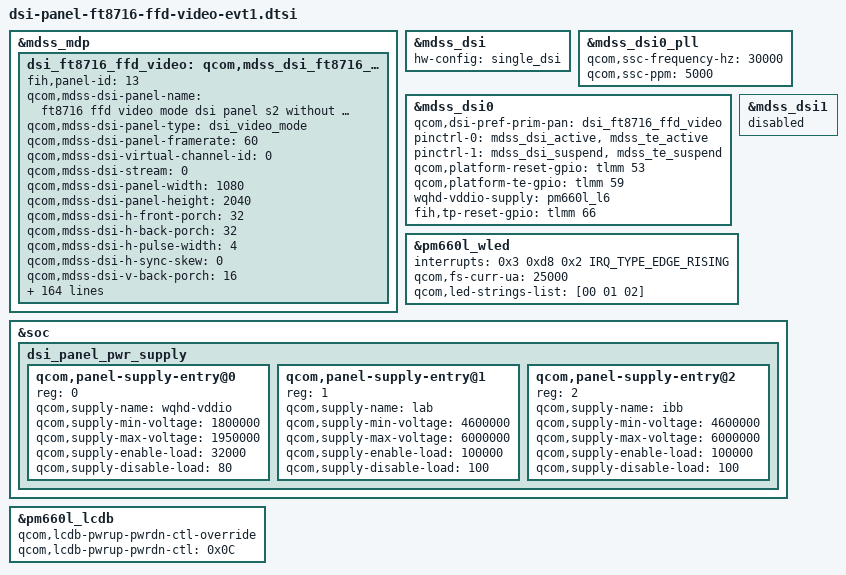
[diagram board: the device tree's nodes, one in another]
/* Copyright (c) 2015, The Linux Foundation. All rights reserved.
 *
 * This program is free software; you can redistribute it and/or modify
 * it under the terms of the GNU General Public License version 2 and
 * only version 2 as published by the Free Software Foundation.
 *
 * This program is distributed in the hope that it will be useful,
 * but WITHOUT ANY WARRANTY; without even the implied warranty of
 * MERCHANTABILITY or FITNESS FOR A PARTICULAR PURPOSE.  See the
 * GNU General Public License for more details.
 */

/*---------------------------------------------------------------------------
 * Templated from dsi-panel-r69006-1080p-video.dtsi
 *---------------------------------------------------------------------------*/
&mdss_mdp {
	dsi_ft8716_ffd_video: qcom,mdss_dsi_ft8716_ffd_video_s2 {
		fih,panel-id = <13>;
		qcom,mdss-dsi-panel-name = "ft8716 ffd video mode dsi panel s2 without DSC";
		qcom,mdss-dsi-panel-type = "dsi_video_mode";
		qcom,mdss-dsi-panel-framerate = <60>;
		qcom,mdss-dsi-virtual-channel-id = <0>;
		qcom,mdss-dsi-stream = <0>;
		qcom,mdss-dsi-panel-width = <1080>;
		qcom,mdss-dsi-panel-height = <2040>;
		qcom,mdss-dsi-h-front-porch = <32>;
		qcom,mdss-dsi-h-back-porch = <32>;
		qcom,mdss-dsi-h-pulse-width = <4>;
		qcom,mdss-dsi-h-sync-skew = <0>;
		qcom,mdss-dsi-v-back-porch = <16>;
		qcom,mdss-dsi-v-front-porch = <16>;
		qcom,mdss-dsi-v-pulse-width = <2>;
		qcom,mdss-dsi-h-left-border = <0>;
		qcom,mdss-dsi-h-right-border = <0>;
		qcom,mdss-dsi-v-top-border = <0>;
		qcom,mdss-dsi-v-bottom-border = <0>;
		qcom,mdss-dsi-bpp = <24>;
		qcom,mdss-dsi-underflow-color = <0xff>;
		qcom,mdss-dsi-border-color = <0>;
		qcom,mdss-dsi-on-command = [
			// ENABLE CMD2
			29 00 00 00 00 00 02 00 80
			29 00 00 00 00 00 03 FF 00 00
			29 00 00 00 00 00 04 FF 87 16 01
			29 00 00 00 00 00 02 00 80
			29 01 00 00 00 00 03 FF 87 16
			// Config WA
			29 01 00 00 00 00 02 00 80
			29 01 00 00 00 00 0D D8 00 00 00 00 00 00 00 00 02 04 04 06
			29 01 00 00 00 00 02 00 90
			29 01 00 00 00 00 0D D8 01 02 02 04 06 08 0a 0a 0b 0a 0b 0a
			29 01 00 00 00 00 02 00 A0
			29 01 00 00 00 00 0D D8 00 02 02 03 04 06 08 0a 0d 0f 10 13
			29 01 00 00 00 00 02 00 B0
			29 01 00 00 00 00 0D D8 00 00 00 00 01 01 00 00 81 82 82 83
			29 01 00 00 00 00 02 00 C0
			29 01 00 00 00 00 0D D8 84 8a 8d 93 9c a6 af b8 c1 c5 c5 c7
			29 01 00 00 00 00 02 00 D0
			29 01 00 00 00 00 0D D8 02 06 08 0a 10 15 1a 1e 21 22 23 24
			29 01 00 00 00 00 02 00 E0
			29 01 00 00 00 00 04 D8 f7 ee e6
			29 01 00 00 00 00 02 00 C0
			29 01 00 00 00 00 02 D7 41
			// DGAMMA OFF
			29 01 00 00 00 00 02 00 A0
			29 01 00 00 00 00 02 D7 05
			// CE
			29 00 00 00 00 00 02 00 A0
			29 01 00 00 00 00 0D D6 10 09 04 00 00 00 0C 19 13 16 17 16
			29 00 00 00 00 00 02 00 B0
			29 01 00 00 00 00 0D D6 8D 88 87 78 5E 3C 33 33 56 6D 79 84
			29 00 00 00 00 00 02 00 C0
			29 01 00 00 00 00 0D D6 80 80 72 65 55 48 44 55 6B 6F 76 7F
			29 00 00 00 00 00 02 00 D0
			29 01 00 00 00 00 0D D6 67 6A 4F 47 3A 39 36 53 57 5D 5A 58
			// AIE V3
			29 01 00 00 00 00 02 00 01
			29 01 00 00 00 00 02 C6 10
			29 01 00 00 00 00 02 00 00
			29 01 00 00 00 00 13 C8 90 78 56 34 33 33 33 33 33 33 43 44 43 44 44 44 44 54
			29 01 00 00 00 00 02 00 01
			29 01 00 00 00 00 02 C6 11
			29 01 00 00 00 00 02 00 00
			29 01 00 00 00 00 13 C8 90 78 56 34 33 33 22 33 33 43 44 44 43 44 44 44 44 54
			29 01 00 00 00 00 02 00 01
			29 01 00 00 00 00 02 C6 12
			29 01 00 00 00 00 02 00 00
			29 01 00 00 00 00 13 C8 E0 8C 56 33 33 33 33 33 33 33 23 22 33 43 44 44 44 44
			29 01 00 00 00 00 02 00 01
			29 01 00 00 00 00 02 C6 00
			// DISABLE CMD2
			29 00 00 00 00 00 02 00 00
			29 01 00 00 00 00 04 FF 00 00 00
			// ??
			29 00 00 00 00 00 02 00 80
			29 00 00 00 00 00 03 FF 00 00
			// DSI ON
			05 01 00 00 78 00 02 11 00
			05 01 00 00 0a 00 02 35 00
			05 01 00 00 00 00 02 29 00
		];
		qcom,mdss-dsi-off-command = [05 01 00 00 14 00 02 28 00
				 05 01 00 00 78 00 02 10 00];
		qcom,mdss-dsi-on-command-state = "dsi_lp_mode";
		qcom,mdss-dsi-off-command-state = "dsi_hs_mode";
		qcom,mdss-dsi-h-sync-pulse = <0>;
		qcom,mdss-dsi-traffic-mode = "non_burst_sync_event";
		qcom,mdss-dsi-bllp-eof-power-mode;
		qcom,mdss-dsi-bllp-power-mode;
		qcom,mdss-dsi-lane-0-state;
		qcom,mdss-dsi-lane-1-state;
		qcom,mdss-dsi-lane-2-state;
		qcom,mdss-dsi-lane-3-state;
		qcom,mdss-dsi-t-clk-post = <0x0d>;
		qcom,mdss-dsi-t-clk-pre = <0x2d>;
		qcom,esd-check-enabled;
		qcom,mdss-dsi-panel-status-check-mode = "reg_read";
		qcom,mdss-dsi-panel-status-command = [06 01 00 01 00 00 01 0a
		06 01 00 01 00 00 01 0b
		06 01 00 01 00 00 01 0c
		06 01 00 01 00 00 01 0d
		06 01 00 01 00 00 01 0e];
		qcom,mdss-dsi-panel-status-command-state = "dsi_hs_mode";
		qcom,mdss-dsi-panel-status-value = <0x9c>,<0x00>,<0x07>,<0x00>,<0x80>;
		qcom,mdss-dsi-panel-on-check-value = <0x9c>,<0x00>,<0x07>,<0x00>,<0x80>;
		qcom,mdss-dsi-panel-status-read-length = <1>,<1>,<1>,<1>,<1>;
		qcom,mdss-dsi-panel-max-error-count = <3>;
		qcom,mdss-dsi-dma-trigger = "trigger_sw";
		qcom,mdss-dsi-mdp-trigger = "none";
		qcom,mdss-dsi-reset-sequence = <1 1>, <0 1>, <1 15>;

		// dynamic : value 1
		qcom,mdss-dsi-ce-on-command = [
			29 01 00 00 00 00 03 91 00 00
		];

		qcom,mdss-dsi-ce-on-command-test1 = [
			29 01 00 00 00 00 03 91 C0 00
		];

		qcom,mdss-dsi-ce-on-command-test2 = [
			29 01 00 00 00 00 03 91 FF 00
		];

		// standard : value 0
		qcom,mdss-dsi-ce-off-command = [
			29 01 00 00 00 00 03 91 80 00
		];

		qcom,mdss-dsi-ct-normal-command = [
			// Enable CMD2
			29 00 00 00 00 00 04 FF 87 16 01
			29 00 00 00 00 00 02 00 80
			29 01 00 00 00 00 03 FF 87 16
			// Gamma Channel
			29 00 00 00 00 00 02 00 A0
			29 01 00 00 00 00 02 D7 05
			// Select White Point
			29 00 00 00 00 00 02 00 00
			29 01 00 00 00 00 02 94 CA
			// Disable CMD2
			29 00 00 00 00 00 02 00 00
			29 00 00 00 00 00 04 FF 00 00 00
			29 00 00 00 00 00 02 00 80
			29 01 00 00 00 00 03 FF 00 00
		];

		qcom,mdss-dsi-ct-warm-command = [
			// Enable CMD2
			29 00 00 00 00 00 04 FF 87 16 01
			29 00 00 00 00 00 02 00 80
			29 01 00 00 00 00 03 FF 87 16
			// Gamma Channel
			29 00 00 00 00 00 02 00 A0
			29 01 00 00 00 00 02 D7 05
			// Select White Point
			29 00 00 00 00 00 02 00 00
			29 01 00 00 00 00 02 94 D2
			// Disable CMD2
			29 00 00 00 00 00 02 00 00
			29 00 00 00 00 00 04 FF 00 00 00
			29 00 00 00 00 00 02 00 80
			29 01 00 00 00 00 03 FF 00 00
		];

		qcom,mdss-dsi-ct-cold-command = [
			// Enable CMD2
			29 00 00 00 00 00 04 FF 87 16 01
			29 00 00 00 00 00 02 00 80
			29 01 00 00 00 00 03 FF 87 16
			// Gamma Channel
			29 00 00 00 00 00 02 00 A0
			29 01 00 00 00 00 02 D7 05
			// Select White Point
			29 00 00 00 00 00 02 00 00
			29 01 00 00 00 00 02 94 A0
			// Disable CMD2
			29 00 00 00 00 00 02 00 00
			29 00 00 00 00 00 04 FF 00 00 00
			29 00 00 00 00 00 02 00 80
			29 01 00 00 00 00 03 FF 00 00
		];

		// Long packet
		qcom,mdss-dsi-ct-warm-command-backup-1= [
			// ENABLE CMD2
			29 00 00 00 00 00 04 FF 87 16 01
			29 00 00 00 00 00 02 00 80
			29 00 00 00 00 00 03 FF 87 16
			// 0xD7A0 = 0x05
			29 00 00 00 00 00 02 00 A0
			29 01 00 00 00 00 02 D7 05
			// WARM
			29 00 00 00 00 00 02 00 00
			29 01 00 00 00 00 10 EC 00 04 08 0C 00 10 14 18 1C 00 20 28 30 38 F0
			29 00 00 00 00 00 02 00 10
			29 01 00 00 00 00 10 EC 40 49 51 59 6E 61 69 71 79 54 81 89 91 99 55
			29 00 00 00 00 00 02 00 20
			29 01 00 00 00 00 10 EC A1 A9 B0 B9 21 C0 C8 D0 D8 03 E0 E8 F0 F8 00
			29 00 00 00 00 00 02 00 30
			29 01 00 00 00 00 05 EC FC FE FF 00
			29 00 00 00 00 00 02 00 00
			29 01 00 00 00 00 10 ED 00 03 07 0B 18 0E 12 16 19 C6 1D 24 2C 33 8D
			29 00 00 00 00 00 02 00 10
			29 01 00 00 00 00 10 ED 3A 42 49 51 37 58 5F 67 6F 2D 76 7D 85 8C 8D
			29 00 00 00 00 00 02 00 20
			29 01 00 00 00 00 10 ED 93 9A A2 A9 8F B1 B8 BF C7 28 CE D5 DD E5 0D
			29 00 00 00 00 00 02 00 30
			29 01 00 00 00 00 05 ED E8 EA EB 0F
			29 00 00 00 00 00 02 00 00
			29 01 00 00 00 00 10 EE 00 03 07 0A 88 0E 11 15 18 08 1A 22 2A 31 5F
			29 00 00 00 00 00 02 00 10
			29 01 00 00 00 00 10 EE 38 3F 46 4D 55 54 5B 62 69 E9 70 78 7F 86 03
			29 00 00 00 00 00 02 00 20
			29 01 00 00 00 00 10 EE 8D 93 9B A2 58 A9 B0 B7 BE A5 C5 CC D3 DA F2
			29 00 00 00 00 00 02 00 30
			29 01 00 00 00 00 05 EE DE E0 E1 01
			// 0xD7A0 = 0x00
			29 00 00 00 00 00 02 00 A0
			29 00 00 00 00 00 02 D7 00
			// DISABLE CMD2
			29 00 00 00 00 00 02 00 00
			29 01 00 00 00 00 04 FF 00 00 00
		];

		// Long packet with 3 parameters
		qcom,mdss-dsi-ct-warm-command-backup-2 = [
			29 00 00 00 00 00 02 00 00
			29 00 00 00 00 00 04 FF 87 16 01
			29 00 00 00 00 00 02 00 80
			29 01 00 00 00 00 03 FF 87 16
			15 00 00 00 00 00 02 00 A0
			15 01 00 00 00 00 02 D7 00
			// GAMMA
			29 00 00 00 00 00 02 00 00
			29 01 00 00 00 00 04 EC 00 03 07
			29 00 00 00 00 00 02 00 03
			29 01 00 00 00 00 04 EC 0B 18 0E
			29 00 00 00 00 00 02 00 06
			29 01 00 00 00 00 04 EC 12 16 1A
			29 00 00 00 00 00 02 00 09
			29 01 00 00 00 00 04 EC 9B 1E 26
			29 00 00 00 00 00 02 00 0C
			29 01 00 00 00 00 04 EC 2D 34 D1
			29 00 00 00 00 00 02 00 10
			29 01 00 00 00 00 04 EC 3C 44 4C
			29 00 00 00 00 00 02 00 13
			29 01 00 00 00 00 04 EC 54 1E 5B
			29 00 00 00 00 00 02 00 16
			29 01 00 00 00 00 04 EC 63 6A 71
			29 00 00 00 00 00 02 00 19
			29 01 00 00 00 00 04 EC 96 79 80
			29 00 00 00 00 00 02 00 1C
			29 01 00 00 00 00 04 EC 87 8F F4
			29 00 00 00 00 00 02 00 20
			29 01 00 00 00 00 04 EC 95 9D A5
			29 00 00 00 00 00 02 00 23
			29 01 00 00 00 00 04 EC AC 8B B4
			29 00 00 00 00 00 02 00 26
			29 01 00 00 00 00 04 EC BB C3 CA
			29 00 00 00 00 00 02 00 29
			29 01 00 00 00 00 04 EC 89 D2 D9
			29 00 00 00 00 00 02 00 2C
			29 01 00 00 00 00 04 EC E1 E8 48
			29 00 00 00 00 00 02 00 30
			29 01 00 00 00 00 04 EC EC EE EF
			29 00 00 00 00 00 02 00 33
			29 01 00 00 00 00 02 EC 00
			29 00 00 00 00 00 02 00 00
			29 01 00 00 00 00 04 ED 00 03 07
			29 00 00 00 00 00 02 00 03
			29 01 00 00 00 00 04 ED 0B 6C 0F
			29 00 00 00 00 00 02 00 06
			29 01 00 00 00 00 04 ED 13 16 1A
			29 00 00 00 00 00 02 00 09
			29 01 00 00 00 00 04 ED 70 1E 25
			29 00 00 00 00 00 02 00 0C
			29 01 00 00 00 00 04 ED 2D 35 6C
			29 00 00 00 00 00 02 00 10
			29 01 00 00 00 00 04 ED 3C 44 4C
			29 00 00 00 00 00 02 00 13
			29 01 00 00 00 00 04 ED 53 CB 5B
			29 00 00 00 00 00 02 00 16
			29 01 00 00 00 00 04 ED 63 6A 72
			29 00 00 00 00 00 02 00 19
			29 01 00 00 00 00 04 ED 61 79 81
			29 00 00 00 00 00 02 00 1C
			29 01 00 00 00 00 04 ED 89 90 CB
			29 00 00 00 00 00 02 00 20
			29 01 00 00 00 00 04 ED 98 A0 A7
			29 00 00 00 00 00 02 00 23
			29 01 00 00 00 00 04 ED AF 61 B6
			29 00 00 00 00 00 02 00 26
			29 01 00 00 00 00 04 ED BE C6 CD
			29 00 00 00 00 00 02 00 29
			29 01 00 00 00 00 04 ED CB D5 DD
			29 00 00 00 00 00 02 00 2C
			29 01 00 00 00 00 04 ED E4 EC 71
			29 00 00 00 00 00 02 00 30
			29 01 00 00 00 00 04 ED F0 F2 F3
			29 00 00 00 00 00 02 00 33
			29 01 00 00 00 00 02 ED 00
			29 00 00 00 00 00 02 00 00
			29 01 00 00 00 00 04 EE 00 04 07
			29 00 00 00 00 00 02 00 03
			29 01 00 00 00 00 04 EE 0B F0 0F
			29 00 00 00 00 00 02 00 06
			29 01 00 00 00 00 04 EE 12 16 1A
			29 00 00 00 00 00 02 00 09
			29 01 00 00 00 00 04 EE BD 1E 26
			29 00 00 00 00 00 02 00 0C
			29 01 00 00 00 00 04 EE 2E 36 2A
			29 00 00 00 00 00 02 00 10
			29 01 00 00 00 00 04 EE 3D 45 4E
			29 00 00 00 00 00 02 00 13
			29 01 00 00 00 00 04 EE 55 CF 5D
			29 00 00 00 00 00 02 00 16
			29 01 00 00 00 00 04 EE 65 6C 74
			29 00 00 00 00 00 02 00 19
			29 01 00 00 00 00 04 EE 71 7B 83
			29 00 00 00 00 00 02 00 1C
			29 01 00 00 00 00 04 EE 8B 93 FE
			29 00 00 00 00 00 02 00 20
			29 01 00 00 00 00 04 EE 9B A3 AB
			29 00 00 00 00 00 02 00 23
			29 01 00 00 00 00 04 EE B3 BF BB
			29 00 00 00 00 00 02 00 26
			29 01 00 00 00 00 04 EE C3 CB D4
			29 00 00 00 00 00 02 00 29
			29 01 00 00 00 00 04 EE 7B DC E6
			29 00 00 00 00 00 02 00 2C
			29 01 00 00 00 00 04 EE EE F7 39
			29 00 00 00 00 00 02 00 30
			29 01 00 00 00 00 04 EE FB FD FF
			29 00 00 00 00 00 02 00 33
			29 01 00 00 00 00 04 EE 09
			// DISABLE CMD2
			29 00 00 00 00 00 02 00 00
			29 01 00 00 00 00 04 FF 00 00 00
		];

		// Shart packet with 1 parameter
		qcom,mdss-dsi-ct-warm-command-backup-3 = [
			29 00 00 00 00 00 02 00 00
			29 00 00 00 00 00 04 FF 87 16 01
			29 00 00 00 00 00 02 00 80
			29 01 00 00 00 00 03 FF 87 16

			15 00 00 00 00 00 02 00 A0
			15 01 00 00 00 00 02 D7 00

			//00 04 08 0C 00 10 14 18 1C 00 20 28 30 38 F0
			15 00 00 00 00 00 02 00 00
			15 00 00 00 00 00 02 EC 00
			15 00 00 00 00 00 02 00 01
			15 00 00 00 00 00 02 EC 04
			15 00 00 00 00 00 02 00 02
			15 00 00 00 00 00 02 EC 08
			15 00 00 00 00 00 02 00 03
			15 00 00 00 00 00 02 EC 0C
			15 00 00 00 00 00 02 00 04
			15 00 00 00 00 00 02 EC 00
			15 00 00 00 00 00 02 00 05
			15 00 00 00 00 00 02 EC 10
			15 00 00 00 00 00 02 00 06
			15 00 00 00 00 00 02 EC 14
			15 00 00 00 00 00 02 00 07
			15 00 00 00 00 00 02 EC 18
			15 00 00 00 00 00 02 00 08
			15 00 00 00 00 00 02 EC 1C
			15 00 00 00 00 00 02 00 09
			15 00 00 00 00 00 02 EC 00
			15 00 00 00 00 00 02 00 0A
			15 00 00 00 00 00 02 EC 20
			15 00 00 00 00 00 02 00 0B
			15 00 00 00 00 00 02 EC 28
			15 00 00 00 00 00 02 00 0C
			15 00 00 00 00 00 02 EC 30
			15 00 00 00 00 00 02 00 0D
			15 00 00 00 00 00 02 EC 38
			15 00 00 00 00 00 02 00 0E
			15 00 00 00 00 00 02 EC F0

			// 40 49 51 59 6E 61 69 71 79 54 81 89 91 99 55
			15 00 00 00 00 00 02 00 10
			15 00 00 00 00 00 02 EC 40
			15 00 00 00 00 00 02 00 11
			15 00 00 00 00 00 02 EC 49
			15 00 00 00 00 00 02 00 12
			15 00 00 00 00 00 02 EC 51
			15 00 00 00 00 00 02 00 13
			15 00 00 00 00 00 02 EC 59
			15 00 00 00 00 00 02 00 14
			15 00 00 00 00 00 02 EC 6E
			15 00 00 00 00 00 02 00 15
			15 00 00 00 00 00 02 EC 61
			15 00 00 00 00 00 02 00 16
			15 00 00 00 00 00 02 EC 69
			15 00 00 00 00 00 02 00 17
			15 00 00 00 00 00 02 EC 71
			15 00 00 00 00 00 02 00 18
			15 00 00 00 00 00 02 EC 79
			15 00 00 00 00 00 02 00 19
			15 00 00 00 00 00 02 EC 54
			15 00 00 00 00 00 02 00 1A
			15 00 00 00 00 00 02 EC 81
			15 00 00 00 00 00 02 00 1B
			15 00 00 00 00 00 02 EC 89
			15 00 00 00 00 00 02 00 1C
			15 00 00 00 00 00 02 EC 91
			15 00 00 00 00 00 02 00 1D
			15 00 00 00 00 00 02 EC 99
			15 00 00 00 00 00 02 00 1E
			15 00 00 00 00 00 02 EC 55

			// A1 A9 B0 B9 21 C0 C8 D0 D8 03 E0 E8 F0 F8 00
			15 00 00 00 00 00 02 00 20
			15 00 00 00 00 00 02 EC A1
			15 00 00 00 00 00 02 00 21
			15 00 00 00 00 00 02 EC A9
			15 00 00 00 00 00 02 00 22
			15 00 00 00 00 00 02 EC B0
			15 00 00 00 00 00 02 00 23
			15 00 00 00 00 00 02 EC B9
			15 00 00 00 00 00 02 00 24
			15 00 00 00 00 00 02 EC 21
			15 00 00 00 00 00 02 00 25
			15 00 00 00 00 00 02 EC C0
			15 00 00 00 00 00 02 00 26
			15 00 00 00 00 00 02 EC C8
			15 00 00 00 00 00 02 00 27
			15 00 00 00 00 00 02 EC D0
			15 00 00 00 00 00 02 00 28
			15 00 00 00 00 00 02 EC D8
			15 00 00 00 00 00 02 00 29
			15 00 00 00 00 00 02 EC 03
			15 00 00 00 00 00 02 00 2A
			15 00 00 00 00 00 02 EC E0
			15 00 00 00 00 00 02 00 2B
			15 00 00 00 00 00 02 EC E8
			15 00 00 00 00 00 02 00 2C
			15 00 00 00 00 00 02 EC F0
			15 00 00 00 00 00 02 00 2D
			15 00 00 00 00 00 02 EC F8
			15 00 00 00 00 00 02 00 2E
			15 00 00 00 00 00 02 EC 00

			// FC FE FF 00
			15 00 00 00 00 00 02 00 30
			15 00 00 00 00 00 02 EC FC
			15 00 00 00 00 00 02 00 31
			15 00 00 00 00 00 02 EC FE
			15 00 00 00 00 00 02 00 32
			15 00 00 00 00 00 02 EC FF
			15 00 00 00 00 00 02 00 33
			15 01 00 00 00 00 02 EC 00

			//15 00 00 00 00 00 02 00 A0
			//15 00 00 00 00 00 02 D7 00

			29 00 00 00 00 00 02 00 00
			29 01 00 00 00 00 04 FF 00 00 00
		];

		qcom,mdss-dsi-ct-cold-command-backup-1 = [
			// ENABLE CMD2
			29 00 00 00 00 00 04 FF 87 16 01
			29 00 00 00 00 00 02 00 80
			29 00 00 00 00 00 03 FF 87 16
			// 0xD7A0 = 0x05
			29 00 00 00 00 00 02 00 A0
			29 01 00 00 00 00 02 D7 05
			// COLD
			29 00 00 00 00 00 02 00 00
			29 01 00 00 00 00 10 EC 00 03 07 0B 18 0E 12 16 1A 9B 1E 26 2D 34 D1
			29 00 00 00 00 00 02 00 10
			29 01 00 00 00 00 10 EC 3C 44 4C 54 1E 5B 63 6A 71 96 79 80 87 8F F4
			29 00 00 00 00 00 02 00 20
			29 01 00 00 00 00 10 EC 95 9D A5 AC 8B B4 BB C3 CA 89 D2 D9 E1 E8 48
			29 00 00 00 00 00 02 00 30
			29 01 00 00 00 00 05 EC EC EE EF 00
			29 00 00 00 00 00 02 00 00
			29 01 00 00 00 00 10 ED 00 03 07 0B 6C 0F 13 16 1A 70 1E 25 2D 35 6C
			29 00 00 00 00 00 02 00 10
			29 01 00 00 00 00 10 ED 3C 44 4C 53 CB 5B 63 6A 72 61 79 81 89 90 CB
			29 00 00 00 00 00 02 00 20
			29 01 00 00 00 00 10 ED 98 A0 A7 AF 61 B6 BE C6 CD CB D5 DD E4 EC 71
			29 00 00 00 00 00 02 00 30
			29 01 00 00 00 00 05 ED F0 F2 F3 00
			29 00 00 00 00 00 02 00 00
			29 01 00 00 00 00 10 EE 00 04 07 0B F0 0F 12 16 1A BD 1E 26 2E 36 2A
			29 00 00 00 00 00 02 00 10
			29 01 00 00 00 00 10 EE 3D 45 4E 55 CF 5D 65 6C 74 71 7B 83 8B 93 FE
			29 00 00 00 00 00 02 00 20
			29 01 00 00 00 00 10 EE 9B A3 AB B3 BF BB C3 CB D4 7B DC E6 EE F7 39
			29 00 00 00 00 00 02 00 30
			29 01 00 00 00 00 05 EE FB FD FF 09
			// 0xD7A0 = 0x00
			29 00 00 00 00 00 02 00 A0
			29 00 00 00 00 00 02 D7 00
			// DISABLE CMD2
			29 00 00 00 00 00 02 00 00
			29 01 00 00 00 00 04 FF 00 00 00
		];

		qcom,mdss-dsi-blf-10-command = [
			// Enable CMD2
			29 00 00 00 00 00 04 FF 87 16 01
			29 00 00 00 00 00 02 00 80
			29 01 00 00 00 00 03 FF 87 16
			// Gamma Channel
			29 00 00 00 00 00 02 00 A0
			29 01 00 00 00 00 02 D7 05
			// Select White Point
			29 00 00 00 00 00 02 00 00
			29 01 00 00 00 00 02 94 CC
			// Disable CMD2
			29 00 00 00 00 00 02 00 00
			29 00 00 00 00 00 04 FF 00 00 00
			29 00 00 00 00 00 02 00 80
			29 01 00 00 00 00 03 FF 00 00
		];

		qcom,mdss-dsi-blf-30-command = [
			// Enable CMD2
			29 00 00 00 00 00 04 FF 87 16 01
			29 00 00 00 00 00 02 00 80
			29 01 00 00 00 00 03 FF 87 16
			// Gamma Channel
			29 00 00 00 00 00 02 00 A0
			29 01 00 00 00 00 02 D7 05
			// Select White Point
			29 00 00 00 00 00 02 00 00
			29 01 00 00 00 00 02 94 DC
			// Disable CMD2
			29 00 00 00 00 00 02 00 00
			29 00 00 00 00 00 04 FF 00 00 00
			29 00 00 00 00 00 02 00 80
			29 01 00 00 00 00 03 FF 00 00
		];

		qcom,mdss-dsi-blf-50-command = [
			// Enable CMD2
			29 00 00 00 00 00 04 FF 87 16 01
			29 00 00 00 00 00 02 00 80
			29 01 00 00 00 00 03 FF 87 16
			// Gamma Channel
			29 00 00 00 00 00 02 00 A0
			29 01 00 00 00 00 02 D7 05
			// Select White Point
			29 00 00 00 00 00 02 00 00
			29 01 00 00 00 00 02 94 EF
			// Disable CMD2
			29 00 00 00 00 00 02 00 00
			29 00 00 00 00 00 04 FF 00 00 00
			29 00 00 00 00 00 02 00 80
			29 01 00 00 00 00 03 FF 00 00
		];

		qcom,mdss-dsi-blf-75-command = [
			// Enable CMD2
			29 00 00 00 00 00 04 FF 87 16 01
			29 00 00 00 00 00 02 00 80
			29 01 00 00 00 00 03 FF 87 16
			// Gamma Channel
			29 00 00 00 00 00 02 00 A0
			29 01 00 00 00 00 02 D7 05
			// Select White Point
			29 00 00 00 00 00 02 00 00
			29 01 00 00 00 00 02 94 FF
			// Disable CMD2
			29 00 00 00 00 00 02 00 00
			29 00 00 00 00 00 04 FF 00 00 00
			29 00 00 00 00 00 02 00 80
			29 01 00 00 00 00 03 FF 00 00
		];

		// AIE
		qcom,mdss-dsi-aie-off-command = [
			// ENABLE CMD2
			29 00 00 00 00 00 02 00 00
			29 00 00 00 00 00 04 FF 87 16 01
			29 00 00 00 00 00 02 00 80
			29 01 00 00 00 00 03 FF 87 16
			// AIE OFF
			29 00 00 00 00 00 02 00 00
			29 01 00 00 00 00 02 92 00
			// DISABLE CMD2
			29 00 00 00 00 00 02 00 00
			29 00 00 00 00 00 04 FF 00 00 00
			29 00 00 00 00 00 02 00 80
			29 01 00 00 00 00 03 FF 00 00
		];

		qcom,mdss-dsi-aie-low-command = [
			// ENABLE CMD2
			29 00 00 00 00 00 02 00 00
			29 00 00 00 00 00 04 FF 87 16 01
			29 00 00 00 00 00 02 00 80
			29 01 00 00 00 00 03 FF 87 16
			// AIE OFF
			29 00 00 00 00 00 02 00 00
			29 01 00 00 00 00 02 92 80
			// DISABLE CMD2
			29 00 00 00 00 00 02 00 00
			29 00 00 00 00 00 04 FF 00 00 00
			29 00 00 00 00 00 02 00 80
			29 01 00 00 00 00 03 FF 00 00
		];

		qcom,mdss-dsi-aie-mid-command = [
			// ENABLE CMD2
			29 00 00 00 00 00 02 00 00
			29 00 00 00 00 00 04 FF 87 16 01
			29 00 00 00 00 00 02 00 80
			29 01 00 00 00 00 03 FF 87 16
			// AIE OFF
			29 00 00 00 00 00 02 00 00
			29 01 00 00 00 00 02 92 81
			// DISABLE CMD2
			29 00 00 00 00 00 02 00 00
			29 00 00 00 00 00 04 FF 00 00 00
			29 00 00 00 00 00 02 00 80
			29 01 00 00 00 00 03 FF 00 00
		];

		qcom,mdss-dsi-aie-high-command = [
			// ENABLE CMD2
			29 00 00 00 00 00 02 00 00
			29 00 00 00 00 00 04 FF 87 16 01
			29 00 00 00 00 00 02 00 80
			29 01 00 00 00 00 03 FF 87 16
			// AIE OFF
			29 00 00 00 00 00 02 00 00
			29 01 00 00 00 00 02 92 82
			// DISABLE CMD2
			29 00 00 00 00 00 02 00 00
			29 00 00 00 00 00 04 FF 00 00 00
			29 00 00 00 00 00 02 00 80
			29 01 00 00 00 00 03 FF 00 00
		];

		//qcom,mdss-dsi-on-separate-config;

		qcom,mdss-dsi-on-ct-normal-command = [
			// ENABLE CMD2
			29 00 00 00 00 00 04 FF 87 16 01
			29 00 00 00 00 00 02 00 80
			29 00 00 00 00 00 03 FF 87 16
			// NORMAL
			29 00 00 00 00 00 02 00 A0
			29 01 00 00 00 00 02 D7 00
			29 00 00 00 00 00 02 00 00
			29 01 00 00 00 00 10 EC 00 04 08 0C 40 10 14 18 1C 55 20 28 30 38 55
			29 00 00 00 00 00 02 00 10
			29 01 00 00 00 00 10 EC 40 48 50 58 00 60 68 70 78 00 80 88 90 98 00
			29 00 00 00 00 00 02 00 20
			29 01 00 00 00 00 10 EC A0 A8 B0 B8 00 C0 C8 D0 D8 00 E0 E8 F0 F8 00
			29 00 00 00 00 00 02 00 30
			29 01 00 00 00 00 05 EC FC FE FF 00
			29 00 00 00 00 00 02 00 00
			29 01 00 00 00 00 10 ED 00 03 07 0B 6C 0F 13 16 1A B0 1E 26 2D 35 61
			29 00 00 00 00 00 02 00 10
			29 01 00 00 00 00 10 ED 3C 44 4C 53 CB 5B 63 6A 72 21 79 81 89 90 87
			29 00 00 00 00 00 02 00 20
			29 01 00 00 00 00 10 ED 98 9F A7 AF 2D B6 BE C5 CD 77 D4 DC E4 EB EF
			29 00 00 00 00 00 02 00 30
			29 01 00 00 00 00 05 ED F0 F2 F2 31
			29 00 00 00 00 00 02 00 00
			29 01 00 00 00 00 10 EE 00 03 07 0A C0 0E 12 16 1A AF 1E 26 2E 35 C5
			29 00 00 00 00 00 02 00 10
			29 01 00 00 00 00 10 EE 3D 45 4C 53 B6 5B 63 6B 72 81 7A 82 8A 92 06
			29 00 00 00 00 00 02 00 20
			29 01 00 00 00 00 10 EE 99 A1 A9 B1 1B B9 C0 C8 D0 6C D8 E0 E8 F0 E1
			29 00 00 00 00 00 02 00 30
			29 01 00 00 00 00 05 EE F4 F7 F8 37
			// AIE V2
			29 00 00 00 00 00 02 00 01
			29 00 00 00 00 00 02 C6 10
			29 00 00 00 00 00 02 00 00
			29 01 00 00 00 00 13 C8 40 44 44 44 44 44 44 44 44 44 44 44 44 44 44 44 44 44
			29 00 00 00 00 00 02 00 01
			29 00 00 00 00 00 02 C6 11
			29 00 00 00 00 00 02 00 00
			29 01 00 00 00 00 13 C8 40 77 56 34 33 33 33 33 44 44 44 44 44 44 44 44 44 44
			29 00 00 00 00 00 02 00 01
			29 00 00 00 00 00 02 C6 12
			29 00 00 00 00 00 02 00 00
			29 01 00 00 00 00 13 C8 F0 BE 7A 55 55 55 55 34 22 22 22 12 12 12 12 12 33 33
			29 00 00 00 00 00 02 00 01
			29 00 00 00 00 00 02 C6 00
			// CE
			29 00 00 00 00 00 02 00 A0
			29 01 00 00 00 00 0D D6 10 09 04 00 00 00 0C 19 13 16 17 16
			29 00 00 00 00 00 02 00 B0
			29 01 00 00 00 00 0D D6 8D 88 87 78 5E 3C 33 33 56 6D 79 84
			29 00 00 00 00 00 02 00 C0
			29 01 00 00 00 00 0D D6 80 80 72 65 55 48 44 55 6B 6F 76 7F
			29 00 00 00 00 00 02 00 D0
			29 01 00 00 00 00 0D D6 67 6A 4F 47 3A 39 36 53 57 5D 5A 58
			// DISABLE CMD2
			29 00 00 00 00 00 02 00 00
			29 00 00 00 00 00 04 FF 00 00 00
			29 00 00 00 00 00 02 00 80
			29 01 00 00 00 00 03 FF 00 00
			// DSI ON
			05 01 00 00 78 00 02 11 00
			05 01 00 00 0a 00 02 35 00
			05 01 00 00 00 00 02 29 00
		];

		qcom,mdss-dsi-on-ct-warm-command = [
			// ENABLE CMD2
			29 00 00 00 00 00 04 FF 87 16 01
			29 00 00 00 00 00 02 00 80
			29 00 00 00 00 00 03 FF 87 16
			// WARM
			29 00 00 00 00 00 02 00 A0
			29 01 00 00 00 00 02 D7 00
			29 00 00 00 00 00 02 00 00
			29 01 00 00 00 00 10 EC 00 04 08 0C 00 10 14 18 1C 00 20 28 30 38 F0
			29 00 00 00 00 00 02 00 10
			29 01 00 00 00 00 10 EC 40 49 51 59 6E 61 69 71 79 54 81 89 91 99 55
			29 00 00 00 00 00 02 00 20
			29 01 00 00 00 00 10 EC A1 A9 B0 B9 21 C0 C8 D0 D8 03 E0 E8 F0 F8 00
			29 00 00 00 00 00 02 00 30
			29 01 00 00 00 00 05 EC FC FE FF 00
			29 00 00 00 00 00 02 00 00
			29 01 00 00 00 00 10 ED 00 03 07 0B 18 0E 12 16 19 C6 1D 24 2C 33 8D
			29 00 00 00 00 00 02 00 10
			29 01 00 00 00 00 10 ED 3A 42 49 51 37 58 5F 67 6F 2D 76 7D 85 8C 8D
			29 00 00 00 00 00 02 00 20
			29 01 00 00 00 00 10 ED 93 9A A2 A9 8F B1 B8 BF C7 28 CE D5 DD E5 0D
			29 00 00 00 00 00 02 00 30
			29 01 00 00 00 00 05 ED E8 EA EB 0F
			29 00 00 00 00 00 02 00 00
			29 01 00 00 00 00 10 EE 00 03 07 0A 88 0E 11 15 18 08 1A 22 2A 31 5F
			29 00 00 00 00 00 02 00 10
			29 01 00 00 00 00 10 EE 38 3F 46 4D 55 54 5B 62 69 E9 70 78 7F 86 03
			29 00 00 00 00 00 02 00 20
			29 01 00 00 00 00 10 EE 8D 93 9B A2 58 A9 B0 B7 BE A5 C5 CC D3 DA F2
			29 00 00 00 00 00 02 00 30
			29 01 00 00 00 00 05 EE DE E0 E1 01
			// AIE V2
			29 00 00 00 00 00 02 00 01
			29 00 00 00 00 00 02 C6 10
			29 00 00 00 00 00 02 00 00
			29 01 00 00 00 00 13 C8 40 44 44 44 44 44 44 44 44 44 44 44 44 44 44 44 44 44
			29 00 00 00 00 00 02 00 01
			29 00 00 00 00 00 02 C6 11
			29 00 00 00 00 00 02 00 00
			29 01 00 00 00 00 13 C8 40 77 56 34 33 33 33 33 44 44 44 44 44 44 44 44 44 44
			29 00 00 00 00 00 02 00 01
			29 00 00 00 00 00 02 C6 12
			29 00 00 00 00 00 02 00 00
			29 01 00 00 00 00 13 C8 F0 BE 7A 55 55 55 55 34 22 22 22 12 12 12 12 12 33 33
			29 00 00 00 00 00 02 00 01
			29 00 00 00 00 00 02 C6 00
			// CE
			29 00 00 00 00 00 02 00 A0
			29 01 00 00 00 00 0D D6 10 09 04 00 00 00 0C 19 13 16 17 16
			29 00 00 00 00 00 02 00 B0
			29 01 00 00 00 00 0D D6 8D 88 87 78 5E 3C 33 33 56 6D 79 84
			29 00 00 00 00 00 02 00 C0
			29 01 00 00 00 00 0D D6 80 80 72 65 55 48 44 55 6B 6F 76 7F
			29 00 00 00 00 00 02 00 D0
			29 01 00 00 00 00 0D D6 67 6A 4F 47 3A 39 36 53 57 5D 5A 58
			// DISABLE CMD2
			29 00 00 00 00 00 02 00 00
			29 00 00 00 00 00 04 FF 00 00 00
			29 00 00 00 00 00 02 00 80
			29 01 00 00 00 00 03 FF 00 00
			// DSI ON
			05 01 00 00 78 00 02 11 00
			05 01 00 00 0a 00 02 35 00
			05 01 00 00 00 00 02 29 00
		];

		qcom,mdss-dsi-on-ct-cold-command = [
			// ENABLE CMD2
			29 00 00 00 00 00 04 FF 87 16 01
			29 00 00 00 00 00 02 00 80
			29 00 00 00 00 00 03 FF 87 16
			// COLD
			29 00 00 00 00 00 02 00 A0
			29 01 00 00 00 00 02 D7 00
			29 00 00 00 00 00 02 00 00
			29 01 00 00 00 00 10 EC 00 03 07 0B 18 0E 12 16 1A 9B 1E 26 2D 34 D1
			29 00 00 00 00 00 02 00 10
			29 01 00 00 00 00 10 EC 3C 44 4C 54 1E 5B 63 6A 71 96 79 80 87 8F F4
			29 00 00 00 00 00 02 00 20
			29 01 00 00 00 00 10 EC 95 9D A5 AC 8B B4 BB C3 CA 89 D2 D9 E1 E8 48
			29 00 00 00 00 00 02 00 30
			29 01 00 00 00 00 05 EC EC EE EF 00
			29 00 00 00 00 00 02 00 00
			29 01 00 00 00 00 10 ED 00 03 07 0B 6C 0F 13 16 1A 70 1E 25 2D 35 6C
			29 00 00 00 00 00 02 00 10
			29 01 00 00 00 00 10 ED 3C 44 4C 53 CB 5B 63 6A 72 61 79 81 89 90 CB
			29 00 00 00 00 00 02 00 20
			29 01 00 00 00 00 10 ED 98 A0 A7 AF 61 B6 BE C6 CD CB D5 DD E4 EC 71
			29 00 00 00 00 00 02 00 30
			29 01 00 00 00 00 05 ED F0 F2 F3 00
			29 00 00 00 00 00 02 00 00
			29 01 00 00 00 00 10 EE 00 04 07 0B F0 0F 12 16 1A BD 1E 26 2E 36 2A
			29 00 00 00 00 00 02 00 10
			29 01 00 00 00 00 10 EE 3D 45 4E 55 CF 5D 65 6C 74 71 7B 83 8B 93 FE
			29 00 00 00 00 00 02 00 20
			29 01 00 00 00 00 10 EE 9B A3 AB B3 BF BB C3 CB D4 7B DC E6 EE F7 39
			29 00 00 00 00 00 02 00 30
			29 01 00 00 00 00 05 EE FB FD FF 09
			// AIE V2
			29 00 00 00 00 00 02 00 01
			29 00 00 00 00 00 02 C6 10
			29 00 00 00 00 00 02 00 00
			29 01 00 00 00 00 13 C8 40 44 44 44 44 44 44 44 44 44 44 44 44 44 44 44 44 44
			29 00 00 00 00 00 02 00 01
			29 00 00 00 00 00 02 C6 11
			29 00 00 00 00 00 02 00 00
			29 01 00 00 00 00 13 C8 40 77 56 34 33 33 33 33 44 44 44 44 44 44 44 44 44 44
			29 00 00 00 00 00 02 00 01
			29 00 00 00 00 00 02 C6 12
			29 00 00 00 00 00 02 00 00
			29 01 00 00 00 00 13 C8 F0 BE 7A 55 55 55 55 34 22 22 22 12 12 12 12 12 33 33
			29 00 00 00 00 00 02 00 01
			29 00 00 00 00 00 02 C6 00
			// CE
			29 00 00 00 00 00 02 00 A0
			29 01 00 00 00 00 0D D6 10 09 04 00 00 00 0C 19 13 16 17 16
			29 00 00 00 00 00 02 00 B0
			29 01 00 00 00 00 0D D6 8D 88 87 78 5E 3C 33 33 56 6D 79 84
			29 00 00 00 00 00 02 00 C0
			29 01 00 00 00 00 0D D6 80 80 72 65 55 48 44 55 6B 6F 76 7F
			29 00 00 00 00 00 02 00 D0
			29 01 00 00 00 00 0D D6 67 6A 4F 47 3A 39 36 53 57 5D 5A 58
			// DISABLE CMD2
			29 00 00 00 00 00 02 00 00
			29 00 00 00 00 00 04 FF 00 00 00
			29 00 00 00 00 00 02 00 80
			29 01 00 00 00 00 03 FF 00 00
			// DSI ON
			05 01 00 00 78 00 02 11 00
			05 01 00 00 0a 00 02 35 00
			05 01 00 00 00 00 02 29 00
		];

		qcom,mdss-dsi-on-blf-10-command = [
			// ENABLE CMD2
			29 00 00 00 00 00 04 FF 87 16 01
			29 00 00 00 00 00 02 00 80
			29 00 00 00 00 00 03 FF 87 16
			// BLF10
			29 00 00 00 00 00 02 00 A0
			29 01 00 00 00 00 02 D7 00
			29 00 00 00 00 00 02 00 00
			29 01 00 00 00 00 10 EC 00 04 08 0C 00 10 14 18 1C 00 20 28 30 38 BE
			29 00 00 00 00 00 02 00 10
			29 01 00 00 00 00 10 EC 40 49 51 59 A2 61 69 71 79 AA 81 89 91 99 AA
			29 00 00 00 00 00 02 00 20
			29 01 00 00 00 00 10 EC A1 A9 B1 B9 1A C0 C8 D0 D8 13 E0 E8 EF F7 F0
			29 00 00 00 00 00 02 00 30
			29 01 00 00 00 00 05 EC FB FE FF 03
			29 00 00 00 00 00 02 00 00
			29 01 00 00 00 00 10 ED 00 03 07 0B BC 0F 13 17 1B 5A 1F 27 2E 36 B1
			29 00 00 00 00 00 02 00 10
			29 01 00 00 00 00 10 ED 3E 46 4E 55 C5 5D 65 6D 75 1A 7C 84 8C 94 6F
			29 00 00 00 00 00 02 00 20
			29 01 00 00 00 00 10 ED 9C A4 AC B3 80 BB C3 CB D3 05 DA E2 EA F1 CA
			29 00 00 00 00 00 02 00 30
			29 01 00 00 00 00 05 ED F6 F8 F9 00
			29 00 00 00 00 00 02 00 00
			29 01 00 00 00 00 10 EE 00 03 07 0B 6C 0F 12 16 19 DC 1D 25 2C 34 77
			29 00 00 00 00 00 02 00 10
			29 01 00 00 00 00 10 EE 3B 43 4A 52 63 59 61 68 70 27 77 7F 86 8E 76
			29 00 00 00 00 00 02 00 20
			29 01 00 00 00 00 10 EE 95 9D A4 AC 77 B3 BC C3 CA E3 D2 DA E1 E9 22
			29 00 00 00 00 00 02 00 30
			29 01 00 00 00 00 05 EE EC EF F0 03
			// AIE V2
			29 00 00 00 00 00 02 00 01
			29 00 00 00 00 00 02 C6 10
			29 00 00 00 00 00 02 00 00
			29 01 00 00 00 00 13 C8 40 44 44 44 44 44 44 44 44 44 44 44 44 44 44 44 44 44
			29 00 00 00 00 00 02 00 01
			29 00 00 00 00 00 02 C6 11
			29 00 00 00 00 00 02 00 00
			29 01 00 00 00 00 13 C8 40 77 56 34 33 33 33 33 44 44 44 44 44 44 44 44 44 44
			29 00 00 00 00 00 02 00 01
			29 00 00 00 00 00 02 C6 12
			29 00 00 00 00 00 02 00 00
			29 01 00 00 00 00 13 C8 F0 BE 7A 55 55 55 55 34 22 22 22 12 12 12 12 12 33 33
			29 00 00 00 00 00 02 00 01
			29 00 00 00 00 00 02 C6 00
			// CE
			29 00 00 00 00 00 02 00 A0
			29 01 00 00 00 00 0D D6 10 09 04 00 00 00 0C 19 13 16 17 16
			29 00 00 00 00 00 02 00 B0
			29 01 00 00 00 00 0D D6 8D 88 87 78 5E 3C 33 33 56 6D 79 84
			29 00 00 00 00 00 02 00 C0
			29 01 00 00 00 00 0D D6 80 80 72 65 55 48 44 55 6B 6F 76 7F
			29 00 00 00 00 00 02 00 D0
			29 01 00 00 00 00 0D D6 67 6A 4F 47 3A 39 36 53 57 5D 5A 58
			// DISABLE CMD2
			29 00 00 00 00 00 02 00 00
			29 00 00 00 00 00 04 FF 00 00 00
			29 00 00 00 00 00 02 00 80
			29 01 00 00 00 00 03 FF 00 00
			// DSI ON
			05 01 00 00 78 00 02 11 00
			05 01 00 00 0a 00 02 35 00
			05 01 00 00 00 00 02 29 00
		];

		qcom,mdss-dsi-on-blf-30-command = [
			// ENABLE CMD2
			29 00 00 00 00 00 04 FF 87 16 01
			29 00 00 00 00 00 02 00 80
			29 00 00 00 00 00 03 FF 87 16
			// BLF30
			29 00 00 00 00 00 02 00 A0
			29 01 00 00 00 00 02 D7 00
			29 00 00 00 00 00 02 00 00
			29 01 00 00 00 00 10 EC 00 04 08 0C 00 10 14 18 1C E0 20 28 30 38 FF
			29 00 00 00 00 00 02 00 10
			29 01 00 00 00 00 10 EC 40 49 51 59 A2 61 69 71 79 55 81 89 91 99 59
			29 00 00 00 00 00 02 00 20
			29 01 00 00 00 00 10 EC A1 A9 B1 B9 45 C1 C8 D0 D8 00 E0 E8 F0 F8 04
			29 00 00 00 00 00 02 00 30
			29 01 00 00 00 00 05 EC FB FE FF 03
			29 00 00 00 00 00 02 00 00
			29 01 00 00 00 00 10 ED 00 03 07 0B FC 0F 13 17 1B 6A 1F 27 2F 36 C1
			29 00 00 00 00 00 02 00 10
			29 01 00 00 00 00 10 ED 3E 46 4E 56 58 5E 65 6D 75 BC 7D 85 8D 95 05
			29 00 00 00 00 00 02 00 20
			29 01 00 00 00 00 10 ED 9C A4 AC B4 6B BC C4 CB D3 F1 DB E3 EB F3 16
			29 00 00 00 00 00 02 00 30
			29 01 00 00 00 00 05 ED F6 F9 FA 03
			29 00 00 00 00 00 02 00 00
			29 01 00 00 00 00 10 EE 00 03 06 0A 74 0D 11 14 18 37 1B 22 29 30 FC
			29 00 00 00 00 00 02 00 10
			29 01 00 00 00 00 10 EE 37 3E 45 4C DF 53 5A 61 68 FF 6F 76 7D 84 DF
			29 00 00 00 00 00 02 00 20
			29 01 00 00 00 00 10 EE 8B 92 99 A0 7F A7 AE B5 BC FF C3 CA D1 D8 FF
			29 00 00 00 00 00 02 00 30
			29 01 00 00 00 00 05 EE DC DE DF 00
			// AIE V2
			29 00 00 00 00 00 02 00 01
			29 00 00 00 00 00 02 C6 10
			29 00 00 00 00 00 02 00 00
			29 01 00 00 00 00 13 C8 40 44 44 44 44 44 44 44 44 44 44 44 44 44 44 44 44 44
			29 00 00 00 00 00 02 00 01
			29 00 00 00 00 00 02 C6 11
			29 00 00 00 00 00 02 00 00
			29 01 00 00 00 00 13 C8 40 77 56 34 33 33 33 33 44 44 44 44 44 44 44 44 44 44
			29 00 00 00 00 00 02 00 01
			29 00 00 00 00 00 02 C6 12
			29 00 00 00 00 00 02 00 00
			29 01 00 00 00 00 13 C8 F0 BE 7A 55 55 55 55 34 22 22 22 12 12 12 12 12 33 33
			29 00 00 00 00 00 02 00 01
			29 00 00 00 00 00 02 C6 00
			// CE
			29 00 00 00 00 00 02 00 A0
			29 01 00 00 00 00 0D D6 10 09 04 00 00 00 0C 19 13 16 17 16
			29 00 00 00 00 00 02 00 B0
			29 01 00 00 00 00 0D D6 8D 88 87 78 5E 3C 33 33 56 6D 79 84
			29 00 00 00 00 00 02 00 C0
			29 01 00 00 00 00 0D D6 80 80 72 65 55 48 44 55 6B 6F 76 7F
			29 00 00 00 00 00 02 00 D0
			29 01 00 00 00 00 0D D6 67 6A 4F 47 3A 39 36 53 57 5D 5A 58
			// DISABLE CMD2
			29 00 00 00 00 00 02 00 00
			29 00 00 00 00 00 04 FF 00 00 00
			29 00 00 00 00 00 02 00 80
			29 01 00 00 00 00 03 FF 00 00
			// DSI ON
			05 01 00 00 78 00 02 11 00
			05 01 00 00 0a 00 02 35 00
			05 01 00 00 00 00 02 29 00
		];

		qcom,mdss-dsi-on-blf-50-command = [
			// ENABLE CMD2
			29 00 00 00 00 00 04 FF 87 16 01
			29 00 00 00 00 00 02 00 80
			29 00 00 00 00 00 03 FF 87 16
			// BLF50
			29 00 00 00 00 00 02 00 A0
			29 01 00 00 00 00 02 D7 00
			29 00 00 00 00 00 02 00 00
			29 01 00 00 00 00 10 EC 00 04 08 0C 00 10 14 18 1C 00 20 28 30 38 60
			29 00 00 00 00 00 02 00 10
			29 01 00 00 00 00 10 EC 40 48 50 59 B0 61 68 70 78 59 80 88 90 98 65
			29 00 00 00 00 00 02 00 20
			29 01 00 00 00 00 10 EC A0 A8 B0 B8 65 C0 C8 D0 D8 00 E0 E8 F0 F8 00
			29 00 00 00 00 00 02 00 30
			29 01 00 00 00 00 05 EC FC FE FF 01
			29 00 00 00 00 00 02 00 00
			29 01 00 00 00 00 10 ED 00 03 07 0B 6C 0F 12 16 1A BC 1E 25 2D 35 2D
			29 00 00 00 00 00 02 00 10
			29 01 00 00 00 00 10 ED 3C 43 4B 53 90 5B 62 6A 71 9B 79 81 88 90 61
			29 00 00 00 00 00 02 00 20
			29 01 00 00 00 00 10 ED 97 9F A7 AE 87 B6 BD C5 CC DC D4 DC E3 EB 72
			29 00 00 00 00 00 02 00 30
			29 01 00 00 00 00 05 ED EF F1 F2 01
			29 00 00 00 00 00 02 00 00
			29 01 00 00 00 00 10 EE 00 03 06 09 00 0B 0E 11 14 AD 17 1D 24 2A 04
			29 00 00 00 00 00 02 00 10
			29 01 00 00 00 00 10 EE 30 36 3C 42 40 48 4E 54 5A 55 60 66 6C 72 55
			29 00 00 00 00 00 02 00 20
			29 01 00 00 00 00 10 EE 78 7E 84 8A A5 90 96 9C A2 AA A8 AE B4 BA AA
			29 00 00 00 00 00 02 00 30
			29 01 00 00 00 00 05 EE BD BF C0 03
			// AIE V2
			29 00 00 00 00 00 02 00 01
			29 00 00 00 00 00 02 C6 10
			29 00 00 00 00 00 02 00 00
			29 01 00 00 00 00 13 C8 40 44 44 44 44 44 44 44 44 44 44 44 44 44 44 44 44 44
			29 00 00 00 00 00 02 00 01
			29 00 00 00 00 00 02 C6 11
			29 00 00 00 00 00 02 00 00
			29 01 00 00 00 00 13 C8 40 77 56 34 33 33 33 33 44 44 44 44 44 44 44 44 44 44
			29 00 00 00 00 00 02 00 01
			29 00 00 00 00 00 02 C6 12
			29 00 00 00 00 00 02 00 00
			29 01 00 00 00 00 13 C8 F0 BE 7A 55 55 55 55 34 22 22 22 12 12 12 12 12 33 33
			29 00 00 00 00 00 02 00 01
			29 00 00 00 00 00 02 C6 00
			// CE
			29 00 00 00 00 00 02 00 A0
			29 01 00 00 00 00 0D D6 10 09 04 00 00 00 0C 19 13 16 17 16
			29 00 00 00 00 00 02 00 B0
			29 01 00 00 00 00 0D D6 8D 88 87 78 5E 3C 33 33 56 6D 79 84
			29 00 00 00 00 00 02 00 C0
			29 01 00 00 00 00 0D D6 80 80 72 65 55 48 44 55 6B 6F 76 7F
			29 00 00 00 00 00 02 00 D0
			29 01 00 00 00 00 0D D6 67 6A 4F 47 3A 39 36 53 57 5D 5A 58
			// DISABLE CMD2
			29 00 00 00 00 00 02 00 00
			29 00 00 00 00 00 04 FF 00 00 00
			29 00 00 00 00 00 02 00 80
			29 01 00 00 00 00 03 FF 00 00
			// DSI ON
			05 01 00 00 78 00 02 11 00
			05 01 00 00 0a 00 02 35 00
			05 01 00 00 00 00 02 29 00
		];

		qcom,mdss-dsi-on-blf-75-command = [
			// ENABLE CMD2
			29 00 00 00 00 00 04 FF 87 16 01
			29 00 00 00 00 00 02 00 80
			29 00 00 00 00 00 03 FF 87 16
			// BLF75
			29 00 00 00 00 00 02 00 A0
			29 01 00 00 00 00 02 D7 00
			29 00 00 00 00 00 02 00 00
			29 01 00 00 00 00 10 EC 00 04 08 0C 00 10 14 18 1C A0 20 28 30 38 FF
			29 00 00 00 00 00 02 00 10
			29 01 00 00 00 00 10 EC 40 48 50 58 A4 60 68 70 78 AA 80 88 90 98 26
			29 00 00 00 00 00 02 00 20
			29 01 00 00 00 00 10 EC A0 A8 B0 B8 00 C0 C8 CF D8 30 E0 E8 F0 F8 00
			29 00 00 00 00 00 02 00 30
			29 01 00 00 00 00 05 EC FC FE FF 01
			29 00 00 00 00 00 02 00 00
			29 01 00 00 00 00 10 ED 00 03 07 0A C8 0E 12 15 19 61 1C 24 2B 32 93
			29 00 00 00 00 00 02 00 10
			29 01 00 00 00 00 10 ED 39 3F 46 4E 05 55 5D 64 6B B6 72 79 80 87 95
			29 00 00 00 00 00 02 00 20
			29 01 00 00 00 00 10 ED 8F 96 9D A4 94 AC B4 BB C2 96 C9 D1 D8 DF 45
			29 00 00 00 00 00 02 00 30
			29 01 00 00 00 00 05 ED E3 E5 E6 02
			29 00 00 00 00 00 02 00 00
			29 01 00 00 00 00 10 EE 00 01 02 04 A8 06 09 0B 0F 37 11 16 1B 20 06
			29 00 00 00 00 00 02 00 10
			29 01 00 00 00 00 10 EE 25 29 2E 33 1C 37 3C 41 45 86 4A 4E 53 58 2D
			29 00 00 00 00 00 02 00 20
			29 01 00 00 00 00 10 EE 5C 61 66 6A CB 6F 74 78 7D 61 82 86 8B 8F D8
			29 00 00 00 00 00 02 00 30
			29 01 00 00 00 00 05 EE 92 93 94 06
			// AIE V2
			29 00 00 00 00 00 02 00 01
			29 00 00 00 00 00 02 C6 10
			29 00 00 00 00 00 02 00 00
			29 01 00 00 00 00 13 C8 40 44 44 44 44 44 44 44 44 44 44 44 44 44 44 44 44 44
			29 00 00 00 00 00 02 00 01
			29 00 00 00 00 00 02 C6 11
			29 00 00 00 00 00 02 00 00
			29 01 00 00 00 00 13 C8 40 77 56 34 33 33 33 33 44 44 44 44 44 44 44 44 44 44
			29 00 00 00 00 00 02 00 01
			29 00 00 00 00 00 02 C6 12
			29 00 00 00 00 00 02 00 00
			29 01 00 00 00 00 13 C8 F0 BE 7A 55 55 55 55 34 22 22 22 12 12 12 12 12 33 33
			29 00 00 00 00 00 02 00 01
			29 00 00 00 00 00 02 C6 00
			// CE
			29 00 00 00 00 00 02 00 A0
			29 01 00 00 00 00 0D D6 10 09 04 00 00 00 0C 19 13 16 17 16
			29 00 00 00 00 00 02 00 B0
			29 01 00 00 00 00 0D D6 8D 88 87 78 5E 3C 33 33 56 6D 79 84
			29 00 00 00 00 00 02 00 C0
			29 01 00 00 00 00 0D D6 80 80 72 65 55 48 44 55 6B 6F 76 7F
			29 00 00 00 00 00 02 00 D0
			29 01 00 00 00 00 0D D6 67 6A 4F 47 3A 39 36 53 57 5D 5A 58
			// DISABLE CMD2
			29 00 00 00 00 00 02 00 00
			29 00 00 00 00 00 04 FF 00 00 00
			29 00 00 00 00 00 02 00 80
			29 01 00 00 00 00 03 FF 00 00
			// DSI ON
			05 01 00 00 78 00 02 11 00
			05 01 00 00 0a 00 02 35 00
			05 01 00 00 00 00 02 29 00
		];

		qcom,mdss-dsi-cabc-off-command = [
			15 01 00 00 05 00 02 55 00
		];

		qcom,mdss-dsi-cabc-ui-command = [
			15 01 00 00 05 00 02 55 01
		];

		qcom,mdss-dsi-cabc-still-command = [
			15 01 00 00 05 00 02 55 02
		];

		qcom,mdss-dsi-cabc-moving-command = [
			15 01 00 00 05 00 02 55 03
		];

		qcom,mdss-dsi-ce-on-command-state = "dsi_hs_mode";
		qcom,mdss-dsi-ce-on-command-state-test1 = "dsi_hs_mode";
		qcom,mdss-dsi-ce-on-command-state-test2 = "dsi_hs_mode";
		qcom,mdss-dsi-ce-off-command-state = "dsi_hs_mode";

		qcom,mdss-dsi-ct-normal-command-state = "dsi_lp_mode";
		qcom,mdss-dsi-ct-warm-command-state = "dsi_lp_mode";
		qcom,mdss-dsi-ct-cold-command-state = "dsi_lp_mode";
		qcom,mdss-dsi-blf-10-command-state = "dsi_lp_mode";
		qcom,mdss-dsi-blf-30-command-state = "dsi_lp_mode";
		qcom,mdss-dsi-blf-50-command-state = "dsi_lp_mode";
		qcom,mdss-dsi-blf-75-command-state = "dsi_lp_mode";

		qcom,mdss-dsi-aie-off-command-state = "dsi_lp_mode";
		qcom,mdss-dsi-aie-low-command-state = "dsi_lp_mode";
		qcom,mdss-dsi-aie-mid-command-state = "dsi_lp_mode";
		qcom,mdss-dsi-aie-high-command-state = "dsi_lp_mode";

		// PURPOSE: reduce resume delay
		qcom,mdss-dsi-on-ct-normal-command-state = "dsi_lp_mode";
		qcom,mdss-dsi-on-ct-warm-command-state = "dsi_lp_mode";
		qcom,mdss-dsi-on-ct-cold-command-state = "dsi_lp_mode";
		qcom,mdss-dsi-on-blf-10-command-state = "dsi_lp_mode";
		qcom,mdss-dsi-on-blf-30-command-state = "dsi_lp_mode";
		qcom,mdss-dsi-on-blf-50-command-state = "dsi_lp_mode";
		qcom,mdss-dsi-on-blf-75-command-state = "dsi_lp_mode";

		qcom,mdss-dsi-cabc-off-command-state = "dsi_hs_mode";
		qcom,mdss-dsi-cabc-ui-command-state = "dsi_hs_mode";
		qcom,mdss-dsi-cabc-still-command-state = "dsi_hs_mode";
		qcom,mdss-dsi-cabc-moving-command-state = "dsi_hs_mode";

		qcom,mdss-pan-physical-width-dimension = <65>;
		qcom,mdss-pan-physical-height-dimension = <123>;
	};
};

&dsi_ft8716_ffd_video {
	qcom,mdss-dsi-panel-timings-phy-v2 = [23 1f 07 09 05 03 04 a0
		23 1f 07 09 05 03 04 a0
		23 1f 07 09 05 03 04 a0
		23 1f 07 09 05 03 04 a0
		23 19 08 08 05 03 04 a0];
	qcom,mdss-dsi-bl-pmic-control-type = "bl_ctrl_wled";
	qcom,mdss-dsi-bl-min-level = <1>;
	qcom,mdss-dsi-bl-max-level = <4095>;
	qcom,panel-supply-entries = <&dsi_panel_pwr_supply>;
};

&mdss_dsi {
	hw-config = "single_dsi";
};

&mdss_dsi0_pll {
	qcom,ssc-frequency-hz = <30000>;
	qcom,ssc-ppm = <5000>;
};

&mdss_dsi0 {
	qcom,dsi-pref-prim-pan = <&dsi_ft8716_ffd_video>;
	pinctrl-names = "mdss_default", "mdss_sleep";
	pinctrl-0 = <&mdss_dsi_active &mdss_te_active>;
	pinctrl-1 = <&mdss_dsi_suspend &mdss_te_suspend>;
	qcom,platform-reset-gpio = <&tlmm 53 0>;
	qcom,platform-te-gpio = <&tlmm 59 0>;
	wqhd-vddio-supply = <&pm660l_l6>;
        fih,tp-reset-gpio = <&tlmm 66 0>;
};

&mdss_dsi1 {
	status = "disabled";
};

&pm660l_wled {
	interrupts = <0x3 0xd8 0x2 IRQ_TYPE_EDGE_RISING>;
	interrupt-names = "sc-irq";
	qcom,fs-curr-ua = <25000>;
	qcom,led-strings-list = [00 01 02];
};

&soc {
	/delete-node/ dsi_panel_pwr_supply;
	dsi_panel_pwr_supply: dsi_panel_pwr_supply {
		#address-cells = <1>;
		#size-cells = <0>;

		qcom,panel-supply-entry@0 {
			reg = <0>;
			qcom,supply-name = "wqhd-vddio";
			qcom,supply-min-voltage = <1800000>;
			qcom,supply-max-voltage = <1950000>;
			qcom,supply-enable-load = <32000>;
			qcom,supply-disable-load = <80>;
		};

		qcom,panel-supply-entry@1 {
			reg = <1>;
			qcom,supply-name = "lab";
			qcom,supply-min-voltage = <4600000>;
			qcom,supply-max-voltage = <6000000>;
			qcom,supply-enable-load = <100000>;
			qcom,supply-disable-load = <100>;
		};

		qcom,panel-supply-entry@2 {
			reg = <2>;
			qcom,supply-name = "ibb";
			qcom,supply-min-voltage = <4600000>;
			qcom,supply-max-voltage = <6000000>;
			qcom,supply-enable-load = <100000>;
			qcom,supply-disable-load = <100>;
		};
	};
};

&pm660l_lcdb {
	qcom,lcdb-pwrup-pwrdn-ctl-override;
	qcom,lcdb-pwrup-pwrdn-ctl = /bits/ 8 <0x0C>;
};
